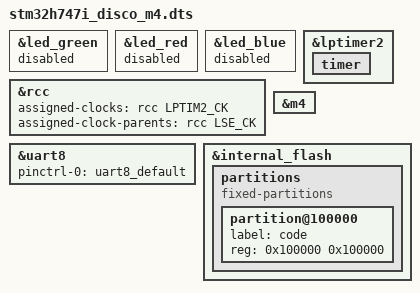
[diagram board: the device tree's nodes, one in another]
// SPDX-FileCopyrightText: 2026 Core Devices LLC
// SPDX-License-Identifier: (GPL-2.0-only OR BSD-2-Clause)

/dts-v1/;

// The kit as the Cortex-M4 runs it: UART8 on the Arduino connector for its console, and LPTIM2 to
// count time, the rest being the Cortex-M7's

#include "st/stm32h747xi_m4.dtsi"
#include "stm32h747i_disco.dtsi"

&led_green {
	status = "disabled";
};

&led_red {
	status = "disabled";
};

&led_blue {
	status = "disabled";
};

// LPTIM2 counts the LSE; the Cortex-M7 sets up the rest of the clocks
&rcc {
	assigned-clocks = <&rcc LPTIM2_CK>;
	assigned-clock-parents = <&rcc LSE_CK>;
};

&lptimer2 {
	status = "okay";

	timer {
		status = "okay";
	};
};

// Powers off when the Cortex-M7 asks
&m4 {
	status = "okay";
};

&uart8 {
	pinctrl-0 = <&uart8_default>;
	pinctrl-names = "default";
	status = "okay";
};

&internal_flash {
	partitions {
		compatible = "fixed-partitions";
		#address-cells = <1>;
		#size-cells = <1>;

		// Bank 2, where the Cortex-M4 boots from
		partition@100000 {
			label = "code";
			reg = <0x100000 0x100000>;
		};
	};
};
